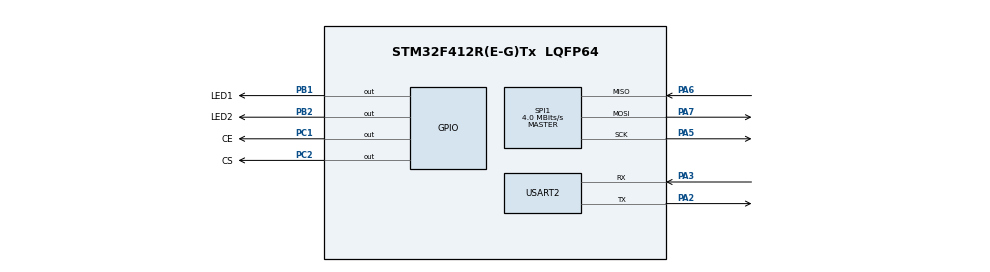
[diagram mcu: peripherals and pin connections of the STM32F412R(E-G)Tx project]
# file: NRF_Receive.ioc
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Mcu.Family=STM32F4
Mcu.Name=STM32F412R(E-G)Tx
Mcu.Package=LQFP64
NVIC.PriorityGroup=NVIC_PRIORITYGROUP_4
PA2.Mode=Asynchronous
PA2.Signal=USART2_TX
PA3.Mode=Asynchronous
PA3.Signal=USART2_RX
PA5.Mode=Full_Duplex_Master
PA5.Signal=SPI1_SCK
PA6.Mode=Full_Duplex_Master
PA6.Signal=SPI1_MISO
PA7.Mode=Full_Duplex_Master
PA7.Signal=SPI1_MOSI
PB1.GPIO_Label=LED1
PB1.Signal=GPIO_Output
PB2.GPIO_Label=LED2
PB2.Signal=GPIO_Output
PC1.GPIO_Label=CE
PC1.Signal=GPIO_Output
PC2.GPIO_Label=CS
PC2.Signal=GPIO_Output
ProjectManager.HeapSize=0x200
ProjectManager.StackSize=0x400
ProjectManager.TargetToolchain=STM32CubeIDE
RCC.CortexFreq_Value=16000000
RCC.USBFreq_Value=96000000
RCC.VCOOutputFreq_Value=192000000
SPI1.BaudRatePrescaler=SPI_BAUDRATEPRESCALER_4
SPI1.CalculateBaudRate=4.0 MBits/s
SPI1.Direction=SPI_DIRECTION_2LINES
SPI1.Mode=SPI_MODE_MASTER
SPI1.VirtualType=VM_MASTER
USART2.VirtualMode=VM_ASYNC
board=custom

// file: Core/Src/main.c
/* USER CODE BEGIN Header */
/**
  ******************************************************************************
  * @file           : main.c
  * @brief          : Main program body
  ******************************************************************************
  * @attention
  *
  * Copyright (c) 2024 STMicroelectronics.
  * All rights reserved.
  *
  * This software is licensed under terms that can be found in the LICENSE file
  * in the root directory of this software component.
  * If no LICENSE file comes with this software, it is provided AS-IS.
  *
  ******************************************************************************
  */
/* USER CODE END Header */
#include "main.h"
#include "spi.h"
#include "usart.h"
#include "gpio.h"

/* USER CODE BEGIN Includes */
#include "NRF_lib.h"
/* USER CODE END Includes */

void SystemClock_Config(void);

/* USER CODE BEGIN 0 */

uint8_t RxAddress[] = {0xEE, 0xDD, 0xCC, 0xBB, 0xAA};  //must be same as tx address sending data
uint8_t RxData[32];

/* USER CODE END 0 */

int main(void)
{

  /* MCU Configuration--------------------------------------------------------*/

  /* Reset of all peripherals, Initializes the Flash interface and the Systick. */
  HAL_Init();

  /* Configure the system clock */
  SystemClock_Config();

  /* Initialize all configured peripherals */
  MX_GPIO_Init();
  MX_SPI1_Init();
  MX_USART2_UART_Init();
  /* USER CODE BEGIN 2 */

  NRF24_Init();
  NRF24_RxMode(RxAddress, 10);

  /* USER CODE END 2 */

  /* Infinite loop */
  while (1)
  {

    /* USER CODE BEGIN 3 */
	  if (isDataAvailable(1) == 1)
	  {
		  HAL_GPIO_WritePin(GPIOB, GPIO_PIN_2, 1);
		  NRF24_Receive(RxData);
		  if(RxData[0]==1)
		  {
			  HAL_GPIO_WritePin(GPIOB, GPIO_PIN_1, 1);
		  }
	  }
  }
  /* USER CODE END 3 */
}

void SystemClock_Config(void)
{
  RCC_OscInitTypeDef RCC_OscInitStruct = {0};
  RCC_ClkInitTypeDef RCC_ClkInitStruct = {0};

  /** Configure the main internal regulator output voltage
  */
  __HAL_RCC_PWR_CLK_ENABLE();
  __HAL_PWR_VOLTAGESCALING_CONFIG(PWR_REGULATOR_VOLTAGE_SCALE1);

  /** Initializes the RCC Oscillators according to the specified parameters
  * in the RCC_OscInitTypeDef structure.
  */
  RCC_OscInitStruct.OscillatorType = RCC_OSCILLATORTYPE_HSI;
  RCC_OscInitStruct.HSIState = RCC_HSI_ON;
  RCC_OscInitStruct.HSICalibrationValue = RCC_HSICALIBRATION_DEFAULT;
  RCC_OscInitStruct.PLL.PLLState = RCC_PLL_NONE;
  if (HAL_RCC_OscConfig(&RCC_OscInitStruct) != HAL_OK)
  {
    Error_Handler();
  }

  /** Initializes the CPU, AHB and APB buses clocks
  */
  RCC_ClkInitStruct.ClockType = RCC_CLOCKTYPE_HCLK|RCC_CLOCKTYPE_SYSCLK
                              |RCC_CLOCKTYPE_PCLK1|RCC_CLOCKTYPE_PCLK2;
  RCC_ClkInitStruct.SYSCLKSource = RCC_SYSCLKSOURCE_HSI;
  RCC_ClkInitStruct.AHBCLKDivider = RCC_SYSCLK_DIV1;
  RCC_ClkInitStruct.APB1CLKDivider = RCC_HCLK_DIV1;
  RCC_ClkInitStruct.APB2CLKDivider = RCC_HCLK_DIV1;

  if (HAL_RCC_ClockConfig(&RCC_ClkInitStruct, FLASH_LATENCY_0) != HAL_OK)
  {
    Error_Handler();
  }
}

void Error_Handler(void)
{
  __disable_irq();
  while (1)
  {
  }
}
